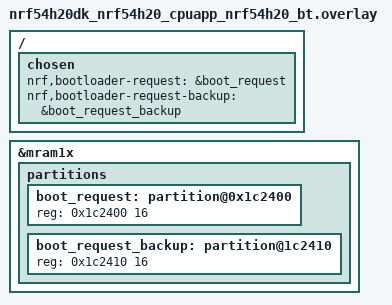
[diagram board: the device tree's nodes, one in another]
/*
 * Copyright (c) 2026 Nordic Semiconductor ASA
 *
 * SPDX-License-Identifier: LicenseRef-Nordic-5-Clause
 */

#include "../dts/nrf54h20dk_nrf54h20_bootchain_bt.dtsi"

&mram1x {
	partitions {
		boot_request: partition@0x1c2400 {
			reg = <0x1c2400 16>;
		};

		boot_request_backup: partition@1c2410 {
			reg = <0x1c2410 16>;
		};
	};
};

/ {
	chosen {
		nrf,bootloader-request = &boot_request;
		nrf,bootloader-request-backup = &boot_request_backup;
	};
};
